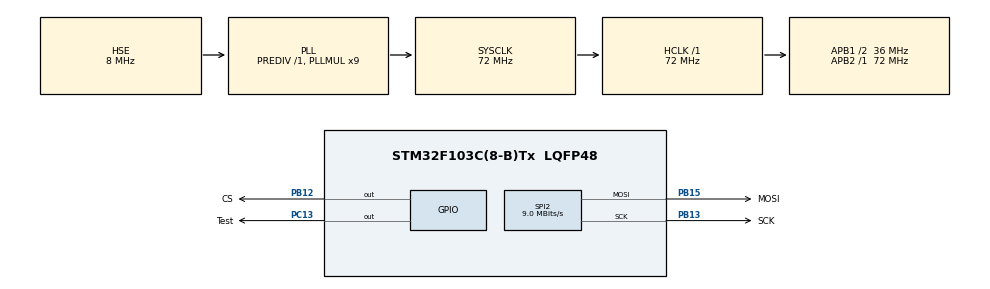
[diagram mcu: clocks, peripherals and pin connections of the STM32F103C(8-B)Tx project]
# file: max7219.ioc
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Dma.Request0=SPI2_TX
Dma.SPI2_TX.0.Direction=DMA_MEMORY_TO_PERIPH
Dma.SPI2_TX.0.Instance=DMA1_Channel5
Dma.SPI2_TX.0.MemDataAlignment=DMA_MDATAALIGN_BYTE
Dma.SPI2_TX.0.MemInc=DMA_MINC_ENABLE
Dma.SPI2_TX.0.Mode=DMA_NORMAL
Dma.SPI2_TX.0.PeriphDataAlignment=DMA_PDATAALIGN_BYTE
Dma.SPI2_TX.0.PeriphInc=DMA_PINC_DISABLE
Dma.SPI2_TX.0.Priority=DMA_PRIORITY_LOW
Mcu.Family=STM32F1
Mcu.Name=STM32F103C(8-B)Tx
Mcu.Package=LQFP48
NVIC.DMA1_Channel5_IRQn=true\:0\:0\:false\:false\:true
NVIC.PriorityGroup=NVIC_PRIORITYGROUP_4
PA13.Mode=Serial_Wire
PA13.Signal=SYS_JTMS-SWDIO
PA14.Mode=Serial_Wire
PA14.Signal=SYS_JTCK-SWCLK
PB12.GPIO_Label=CS
PB12.GPIO_Speed=GPIO_SPEED_FREQ_HIGH
PB12.PinState=GPIO_PIN_SET
PB12.Signal=GPIO_Output
PB13.GPIO_Label=SCK
PB13.Mode=TX_Only_Simplex_Unidirect_Master
PB13.Signal=SPI2_SCK
PB15.GPIO_Label=MOSI
PB15.GPIO_Speed=GPIO_SPEED_FREQ_HIGH
PB15.Mode=TX_Only_Simplex_Unidirect_Master
PB15.Signal=SPI2_MOSI
PC13-TAMPER-RTC.GPIO_Label=Test
PC13-TAMPER-RTC.Signal=GPIO_Output
PD0-OSC_IN.Mode=HSE-External-Oscillator
PD0-OSC_IN.Signal=RCC_OSC_IN
PD1-OSC_OUT.Mode=HSE-External-Oscillator
PD1-OSC_OUT.Signal=RCC_OSC_OUT
ProjectManager.HeapSize=0x200
ProjectManager.StackSize=0x400
ProjectManager.TargetToolchain=MDK-ARM V5
RCC.AHBFreq_Value=72000000
RCC.APB1CLKDivider=RCC_HCLK_DIV2
RCC.APB1Freq_Value=36000000
RCC.APB1TimFreq_Value=72000000
RCC.APB2Freq_Value=72000000
RCC.APB2TimFreq_Value=72000000
RCC.EnbaleCSS=true
RCC.HCLKFreq_Value=72000000
RCC.HSIState=RCC_HSI_ON
RCC.PLLMUL=RCC_PLL_MUL9
RCC.PLLSourceVirtual=RCC_PLLSOURCE_HSE
RCC.SYSCLKFreq_VALUE=72000000
RCC.SYSCLKSource=RCC_SYSCLKSOURCE_PLLCLK
RCC.USBFreq_Value=72000000
SPI2.BaudRatePrescaler=SPI_BAUDRATEPRESCALER_4
SPI2.CalculateBaudRate=9.0 MBits/s
SPI2.DataSize=SPI_DATASIZE_8BIT
SPI2.Mode=SPI_MODE_MASTER
board=max7219

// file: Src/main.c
/**
  ******************************************************************************
  * File Name          : main.c
  * Description        : Main program body
  ******************************************************************************
  *
  * COPYRIGHT(c) 2016 STMicroelectronics
  *
  * Redistribution and use in source and binary forms, with or without modification,
  * are permitted provided that the following conditions are met:
  *   1. Redistributions of source code must retain the above copyright notice,
  *      this list of conditions and the following disclaimer.
  *   2. Redistributions in binary form must reproduce the above copyright notice,
  *      this list of conditions and the following disclaimer in the documentation
  *      and/or other materials provided with the distribution.
  *   3. Neither the name of STMicroelectronics nor the names of its contributors
  *      may be used to endorse or promote products derived from this software
  *      without specific prior written permission.
  *
  * THIS SOFTWARE IS PROVIDED BY THE COPYRIGHT HOLDERS AND CONTRIBUTORS "AS IS"
  * AND ANY EXPRESS OR IMPLIED WARRANTIES, INCLUDING, BUT NOT LIMITED TO, THE
  * IMPLIED WARRANTIES OF MERCHANTABILITY AND FITNESS FOR A PARTICULAR PURPOSE ARE
  * DISCLAIMED. IN NO EVENT SHALL THE COPYRIGHT HOLDER OR CONTRIBUTORS BE LIABLE
  * FOR ANY DIRECT, INDIRECT, INCIDENTAL, SPECIAL, EXEMPLARY, OR CONSEQUENTIAL
  * DAMAGES (INCLUDING, BUT NOT LIMITED TO, PROCUREMENT OF SUBSTITUTE GOODS OR
  * SERVICES; LOSS OF USE, DATA, OR PROFITS; OR BUSINESS INTERRUPTION) HOWEVER
  * CAUSED AND ON ANY THEORY OF LIABILITY, WHETHER IN CONTRACT, STRICT LIABILITY,
  * OR TORT (INCLUDING NEGLIGENCE OR OTHERWISE) ARISING IN ANY WAY OUT OF THE USE
  * OF THIS SOFTWARE, EVEN IF ADVISED OF THE POSSIBILITY OF SUCH DAMAGE.
  *
  ******************************************************************************
  */
#include "stm32f1xx_hal.h"

/* USER CODE BEGIN Includes */
#include "main.h"
/* USER CODE END Includes */

SPI_HandleTypeDef hspi2;
DMA_HandleTypeDef hdma_spi2_tx;

/* USER CODE BEGIN PV */
/* Private variables ---------------------------------------------------------*/

//uint8_t rd[2]={0};
/* USER CODE END PV */

void SystemClock_Config(void);
void Error_Handler(void);
static void MX_GPIO_Init(void);
static void MX_DMA_Init(void);
static void MX_SPI2_Init(void);

/* USER CODE BEGIN PFP */
/* Private function prototypes -----------------------------------------------*/

/* USER CODE END PFP */

int main(void)
{

  /* MCU Configuration----------------------------------------------------------*/

  /* Reset of all peripherals, Initializes the Flash interface and the Systick. */
  HAL_Init();

  /* Configure the system clock */
  SystemClock_Config();

  /* Initialize all configured peripherals */
  MX_GPIO_Init();
  MX_DMA_Init();
  MX_SPI2_Init();

  /* USER CODE BEGIN 2 */
   MAX7219_Init (&hspi2);
  MAX7219_SetDecodeMode (&hspi2,0xFF);
  //MAX7219_SetFloatNumber (&hspi2,-3245.6798,2);

  /* USER CODE END 2 */

  /* Infinite loop */
  /* USER CODE BEGIN WHILE */
  while (1)
  {

     // MAX7219_NoOp (&hspi2);

    //  MAX7219_NoOp (&hspi2);

    //  MAX7219_SetPowerState (&hspi2,1);

//      for(signed long i=-9999;i<=9999;i++)
//     {
//
//      MAX7219_SetIntNumber (&hspi2,i);
// HAL_Delay(1);
//
//     }

      for(float i=0.12345678;i<9999;i++)
     {
         MAX7219_SetFloatNumber (&hspi2,i,7);
          HAL_Delay(50);
     }
//     MAX7219_SetFloatNumber (&hspi2,123.23456789,7);
//HAL_Delay(1000);
//
//      for(unsigned char i=0x00;i<=0x0F;i++)
//      {
//       MAX7219_SetIntensity (&hspi2,i);
//          HAL_Delay(150);
//      }
//
//      HAL_Delay(50);
//      for(unsigned char i=0x0F;i>0x00;i--)
//      {
//       MAX7219_SetIntensity (&hspi2,i);
//          HAL_Delay(150);
//      }
     // MAX7219_Clear (&hspi2);
      HAL_Delay(3000);
   //    MAX7219_SetDisplayTest (&hspi2,1);
    //  HAL_Delay(2000);

    //  MAX7219_SetDisplayTest (&hspi2,0);
    //   HAL_Delay(200);

    //  MAX7219_SetPowerState (&hspi2,0);

  /* USER CODE END WHILE */

  }

}

/** System Clock Configuration
*/
void SystemClock_Config(void)
{

  RCC_OscInitTypeDef RCC_OscInitStruct;
  RCC_ClkInitTypeDef RCC_ClkInitStruct;

  RCC_OscInitStruct.OscillatorType = RCC_OSCILLATORTYPE_HSE;
  RCC_OscInitStruct.HSEState = RCC_HSE_ON;
  RCC_OscInitStruct.HSEPredivValue = RCC_HSE_PREDIV_DIV1;
  RCC_OscInitStruct.PLL.PLLState = RCC_PLL_ON;
  RCC_OscInitStruct.PLL.PLLSource = RCC_PLLSOURCE_HSE;
  RCC_OscInitStruct.PLL.PLLMUL = RCC_PLL_MUL9;
  if (HAL_RCC_OscConfig(&RCC_OscInitStruct) != HAL_OK)
  {
    Error_Handler();
  }

  RCC_ClkInitStruct.ClockType = RCC_CLOCKTYPE_HCLK|RCC_CLOCKTYPE_SYSCLK
                              |RCC_CLOCKTYPE_PCLK1|RCC_CLOCKTYPE_PCLK2;
  RCC_ClkInitStruct.SYSCLKSource = RCC_SYSCLKSOURCE_PLLCLK;
  RCC_ClkInitStruct.AHBCLKDivider = RCC_SYSCLK_DIV1;
  RCC_ClkInitStruct.APB1CLKDivider = RCC_HCLK_DIV2;
  RCC_ClkInitStruct.APB2CLKDivider = RCC_HCLK_DIV1;
  if (HAL_RCC_ClockConfig(&RCC_ClkInitStruct, FLASH_LATENCY_2) != HAL_OK)
  {
    Error_Handler();
  }

  HAL_RCC_EnableCSS();

  HAL_SYSTICK_Config(HAL_RCC_GetHCLKFreq()/1000);

  HAL_SYSTICK_CLKSourceConfig(SYSTICK_CLKSOURCE_HCLK);

  /* SysTick_IRQn interrupt configuration */
  HAL_NVIC_SetPriority(SysTick_IRQn, 0, 0);
}

/* SPI2 init function */
static void MX_SPI2_Init(void)
{

  hspi2.Instance = SPI2;
  hspi2.Init.Mode = SPI_MODE_MASTER;
  hspi2.Init.Direction = SPI_DIRECTION_2LINES;
  hspi2.Init.DataSize = SPI_DATASIZE_8BIT;
  hspi2.Init.CLKPolarity = SPI_POLARITY_LOW;
  hspi2.Init.CLKPhase = SPI_PHASE_1EDGE;
  hspi2.Init.NSS = SPI_NSS_SOFT;
  hspi2.Init.BaudRatePrescaler = SPI_BAUDRATEPRESCALER_4;
  hspi2.Init.FirstBit = SPI_FIRSTBIT_MSB;
  hspi2.Init.TIMode = SPI_TIMODE_DISABLE;
  hspi2.Init.CRCCalculation = SPI_CRCCALCULATION_DISABLE;
  hspi2.Init.CRCPolynomial = 10;
  if (HAL_SPI_Init(&hspi2) != HAL_OK)
  {
    Error_Handler();
  }

}

static void MX_DMA_Init(void)
{
  /* DMA controller clock enable */
  __HAL_RCC_DMA1_CLK_ENABLE();

  /* DMA interrupt init */
  /* DMA1_Channel5_IRQn interrupt configuration */
  HAL_NVIC_SetPriority(DMA1_Channel5_IRQn, 0, 0);
  HAL_NVIC_EnableIRQ(DMA1_Channel5_IRQn);

}

/** Configure pins as
        * Analog
        * Input
        * Output
        * EVENT_OUT
        * EXTI
*/
static void MX_GPIO_Init(void)
{

  GPIO_InitTypeDef GPIO_InitStruct;

  /* GPIO Ports Clock Enable */
  __HAL_RCC_GPIOC_CLK_ENABLE();
  __HAL_RCC_GPIOD_CLK_ENABLE();
  __HAL_RCC_GPIOB_CLK_ENABLE();
  __HAL_RCC_GPIOA_CLK_ENABLE();

  /*Configure GPIO pin Output Level */
  HAL_GPIO_WritePin(Test_GPIO_Port, Test_Pin, GPIO_PIN_RESET);

  /*Configure GPIO pin Output Level */
  HAL_GPIO_WritePin(CS_GPIO_Port, CS_Pin, GPIO_PIN_SET);

  /*Configure GPIO pin : Test_Pin */
  GPIO_InitStruct.Pin = Test_Pin;
  GPIO_InitStruct.Mode = GPIO_MODE_OUTPUT_PP;
  GPIO_InitStruct.Speed = GPIO_SPEED_FREQ_LOW;
  HAL_GPIO_Init(Test_GPIO_Port, &GPIO_InitStruct);

  /*Configure GPIO pin : CS_Pin */
  GPIO_InitStruct.Pin = CS_Pin;
  GPIO_InitStruct.Mode = GPIO_MODE_OUTPUT_PP;
  GPIO_InitStruct.Speed = GPIO_SPEED_FREQ_HIGH;
  HAL_GPIO_Init(CS_GPIO_Port, &GPIO_InitStruct);

}

void Error_Handler(void)
{
  while(1)
  {
  }
}

/************************ (C) COPYRIGHT STMicroelectronics *****END OF FILE****/
